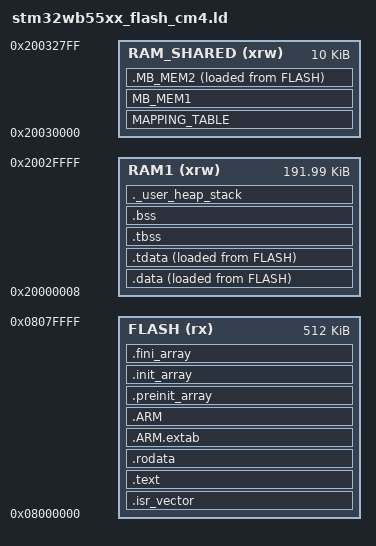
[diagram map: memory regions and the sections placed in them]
/**
*****************************************************************************
**
**  File        : stm32wb55xx_flash_cm4.ld
**
**  Author      : STM32CubeIDE
**
**  Abstract    : Linker script for STM32WB55xx Device
**                     1024Kbytes FLASH
**                      128Kbytes RAM
**
**                Set heap size, stack size and stack location according
**                to application requirements.
**
**                Set memory bank area and size if external memory is used.
**
**  Target      : STMicroelectronics STM32
**
**  Distribution: The file is distributed as is without any warranty
**                of any kind.
**
*****************************************************************************
** @attention
**
** Copyright (c) 2019-2022 STMicroelectronics.
** All rights reserved.
**
** This software is licensed under terms that can be found in the LICENSE file
** in the root directory of this software component.
** If no LICENSE file comes with this software, it is provided AS-IS.
**
*****************************************************************************
*/

/* Entry Point */
ENTRY(Reset_Handler)


/* Specify the memory areas */
MEMORY
{
FLASH (rx)                 : ORIGIN = 0x08000000, LENGTH = 512K
RAM1 (xrw)                 : ORIGIN = 0x20000008, LENGTH = 0x2FFF8
RAM_SHARED (xrw)           : ORIGIN = 0x20030000, LENGTH = 10K
}
/* Highest address of the user mode stack */
_estack = 0x20030000;    /* end of RAM */
/* Generate a link error if heap and stack don't fit into RAM */
_Min_Heap_Size = 0x200;      /* required amount of heap  */
_Min_Stack_Size = 0x400; /* required amount of stack */

/* Define output sections */
SECTIONS
{
  /* The startup code goes first into FLASH */
  .isr_vector :
  {
    . = ALIGN(4);
    KEEP(*(.isr_vector)) /* Startup code */
    . = ALIGN(4);
  } >FLASH

  /* The program code and other data goes into FLASH */
  .text :
  {
    . = ALIGN(4);
    *(.text)           /* .text sections (code) */
    *(.text*)          /* .text* sections (code) */
    *(.glue_7)         /* glue arm to thumb code */
    *(.glue_7t)        /* glue thumb to arm code */
    *(.eh_frame)

    KEEP (*(.init))
    KEEP (*(.fini))

    . = ALIGN(4);
    _etext = .;        /* define a global symbols at end of code */
  } >FLASH

  /* Constant data goes into FLASH */
  .rodata :
  {
    . = ALIGN(4);
    *(.rodata)         /* .rodata sections (constants, strings, etc.) */
    *(.rodata*)        /* .rodata* sections (constants, strings, etc.) */
    . = ALIGN(4);
  } >FLASH

  .ARM.extab (READONLY) : /* The READONLY keyword is only supported in GCC11 and later, remove it if using GCC10 or earlier. */
  {
    *(.ARM.extab* .gnu.linkonce.armextab.*)
  } >FLASH
  .ARM (READONLY) : /* The READONLY keyword is only supported in GCC11 and later, remove it if using GCC10 or earlier. */
  {
    __exidx_start = .;
    *(.ARM.exidx*)
    __exidx_end = .;
  } >FLASH

  .preinit_array (READONLY) : /* The READONLY keyword is only supported in GCC11 and later, remove it if using GCC10 or earlier. */
  {
    PROVIDE_HIDDEN (__preinit_array_start = .);
    KEEP (*(.preinit_array*))
    PROVIDE_HIDDEN (__preinit_array_end = .);
  } >FLASH
  .init_array (READONLY) : /* The READONLY keyword is only supported in GCC11 and later, remove it if using GCC10 or earlier. */
  {
    PROVIDE_HIDDEN (__init_array_start = .);
    KEEP (*(SORT(.init_array.*)))
    KEEP (*(.init_array*))
    PROVIDE_HIDDEN (__init_array_end = .);
  } >FLASH
  .fini_array (READONLY) : /* The READONLY keyword is only supported in GCC11 and later, remove it if using GCC10 or earlier. */
  {
    PROVIDE_HIDDEN (__fini_array_start = .);
    KEEP (*(SORT(.fini_array.*)))
    KEEP (*(.fini_array*))
    PROVIDE_HIDDEN (__fini_array_end = .);
  } >FLASH

  /* used by the startup to initialize data */
  _sidata = LOADADDR(.data);

  /* Initialized data sections goes into RAM, load LMA copy after code */
  .data :
  {
    . = ALIGN(4);
    _sdata = .;        /* create a global symbol at data start */
    *(.data)           /* .data sections */
    *(.data*)          /* .data* sections */

    . = ALIGN(4);
  } >RAM1 AT> FLASH

  /* Initialized TLS data section */
  .tdata : ALIGN(4)
  {
    *(.tdata .tdata.* .gnu.linkonce.td.*)
    . = ALIGN(4);
    _edata = .;        /* define a global symbol at data end */
    PROVIDE(__data_end = .);
    PROVIDE(__tdata_end = .);
  } >RAM1 AT> FLASH

  PROVIDE( __tdata_start = ADDR(.tdata) );
  PROVIDE( __tdata_size = __tdata_end - __tdata_start );

  PROVIDE( __data_start = ADDR(.data) );
  PROVIDE( __data_size = __data_end - __data_start );

  PROVIDE( __tdata_source = LOADADDR(.tdata) );
  PROVIDE( __tdata_source_end = LOADADDR(.tdata) + SIZEOF(.tdata) );
  PROVIDE( __tdata_source_size = __tdata_source_end - __tdata_source );

  PROVIDE( __data_source = LOADADDR(.data) );
  PROVIDE( __data_source_end = __tdata_source_end );
  PROVIDE( __data_source_size = __data_source_end - __data_source );


  /* Uninitialized data section */
  /* Uninitialized TLS data section */
  .tbss (NOLOAD) : ALIGN(4)
  {
    _sbss = .;         /* define a global symbol at bss start */
    __bss_start__ = _sbss;
    *(.tbss .tbss.*)
    . = ALIGN(4);
    PROVIDE( __tbss_end = . );
  } >RAM1

  PROVIDE( __tbss_start = ADDR(.tbss) );
  PROVIDE( __tbss_size = __tbss_end - __tbss_start );
  PROVIDE( __tbss_offset = ADDR(.tbss) - ADDR(.tdata) );

  PROVIDE( __tls_base = __tdata_start );
  PROVIDE( __tls_end = __tbss_end );
  PROVIDE( __tls_size = __tls_end - __tls_base );
  PROVIDE( __tls_align = MAX(ALIGNOF(.tdata), ALIGNOF(.tbss)) );
  PROVIDE( __tls_size_align = (__tls_size + __tls_align - 1) & ~(__tls_align - 1) );
  PROVIDE( __arm32_tls_tcb_offset = MAX(8, __tls_align) );
  PROVIDE( __arm64_tls_tcb_offset = MAX(16, __tls_align) );

  .bss (NOLOAD) : ALIGN(4)
  {
    /* This is used by the startup in order to initialize the .bss section */
    *(.bss)
    *(.bss*)
    *(COMMON)

    . = ALIGN(4);
    _ebss = .;         /* define a global symbol at bss end */
    __bss_end__ = _ebss;
      PROVIDE( __bss_end = .);
  } >RAM1
  PROVIDE( __non_tls_bss_start = ADDR(.bss) );

  PROVIDE( __bss_start = __tbss_start );
  PROVIDE( __bss_size = __bss_end - __bss_start );


  /* User_heap_stack section, used to check that there is enough RAM left */
  ._user_heap_stack (NOLOAD) :
  {
    . = ALIGN(8);
    PROVIDE ( end = . );
    PROVIDE ( _end = . );
    . = . + _Min_Heap_Size;
    . = . + _Min_Stack_Size;
    . = ALIGN(8);
  } >RAM1

  /* Remove information from the standard libraries */
  /DISCARD/ :
  {
    libc.a:* ( * )
    libm.a:* ( * )
    libgcc.a:* ( * )
  }

  .ARM.attributes 0       : { *(.ARM.attributes) }
  MAPPING_TABLE (NOLOAD) : { *(MAPPING_TABLE) } >RAM_SHARED
  MB_MEM1 (NOLOAD)       : { *(MB_MEM1) } >RAM_SHARED

  /* used by the startup to initialize .MB_MEM2 data */
  _siMB_MEM2 = LOADADDR(.MB_MEM2);
  .MB_MEM2 :
  {
    _sMB_MEM2 = . ;
    *(MB_MEM2) ;
    _eMB_MEM2 = . ;
  } >RAM_SHARED AT> FLASH
}


